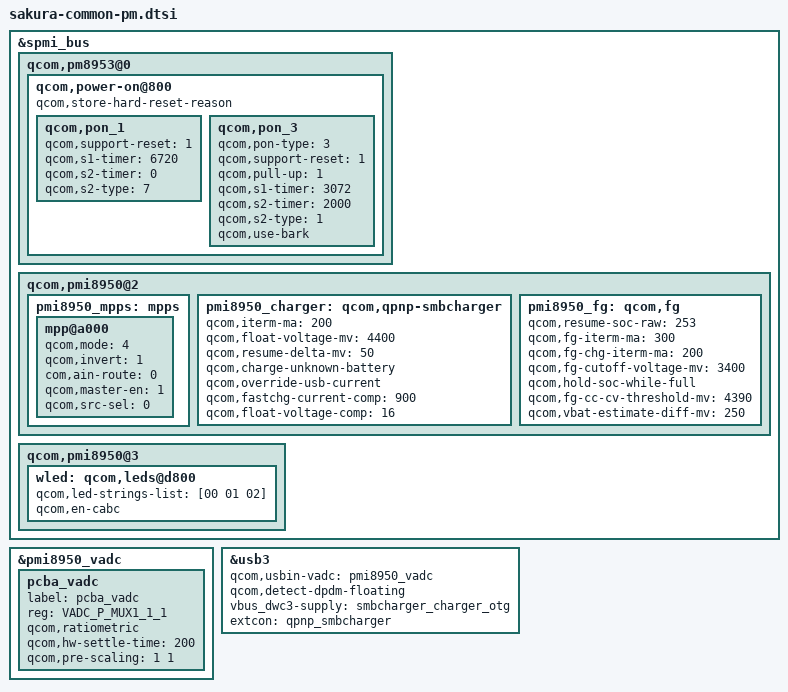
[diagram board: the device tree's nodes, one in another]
/* msm-pm8953 */
&spmi_bus {
	qcom,pm8953@0 {
		qcom,power-on@800 {
			qcom,store-hard-reset-reason;
			qcom,pon_1 {
				qcom,support-reset = <1>;
				qcom,s1-timer = <6720>;
				qcom,s2-timer = <0>;
				qcom,s2-type = <7>;
			};

			qcom,pon_3 {
				qcom,pon-type = <3>;
				qcom,support-reset = <1>;
				qcom,pull-up = <1>;
				qcom,s1-timer = <3072>;
				qcom,s2-timer = <2000>;
				qcom,s2-type = <1>;
				qcom,use-bark;
			};
		};
		/delete-node/ qcom,pm8953_typec@bf00;
	};
};

&pmi8950_vadc {
	pcba_vadc {
		label = "pcba_vadc";
		reg = <VADC_P_MUX1_1_1>;
		qcom,ratiometric;
		qcom,hw-settle-time = <200>;
		qcom,pre-scaling = <1 1>;
	};
};

/* msm-pmi8950 */
&spmi_bus {
	qcom,pmi8950@2 {
		pmi8950_mpps: mpps {
			mpp@a000 {
				qcom,mode = <4>; /* AIN input */
				qcom,invert = <1>; /* Enable MPP */
				com,ain-route = <0>; /* AMUX 5 */
				qcom,master-en = <1>;
				qcom,src-sel = <0>; /* Function constant */
				status = "okay";
			};
		};
		pmi8950_charger: qcom,qpnp-smbcharger {
			qcom,iterm-ma = <200>;
			qcom,float-voltage-mv = <4400>;
			qcom,resume-delta-mv = <50>;
			qcom,charge-unknown-battery;
			/delete-property/ qcom,parallel-usb-min-current-ma;
			/delete-property/ qcom,parallel-usb-9v-min-current-ma;
			/delete-property/ qcom,parallel-allowed-lowering-ma;
			qcom,override-usb-current;
			qcom,fastchg-current-comp = <900>;
			qcom,float-voltage-comp = <16>;
			/delete-property/ qcom,autoadjust-vfloat;
		};
		pmi8950_fg: qcom,fg {
			/delete-property/ qcom,resume-soc;
			qcom,resume-soc-raw = <253>;
			qcom,fg-iterm-ma = <300>;
			qcom,fg-chg-iterm-ma = <200>;
			qcom,fg-cutoff-voltage-mv = <3400>;
			qcom,hold-soc-while-full;
			qcom,fg-cc-cv-threshold-mv =<4390>;
			qcom,vbat-estimate-diff-mv = <250>;
		};
	};
	qcom,pmi8950@3 {
		wled: qcom,leds@d800 {
			qcom,led-strings-list = [00 01 02];
			qcom,en-cabc;
		};
	};
};

&usb3 {
	qcom,usbin-vadc = <&pmi8950_vadc>;
	qcom,detect-dpdm-floating;
	vbus_dwc3-supply = <&smbcharger_charger_otg>;
	extcon = <&qpnp_smbcharger>;
};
